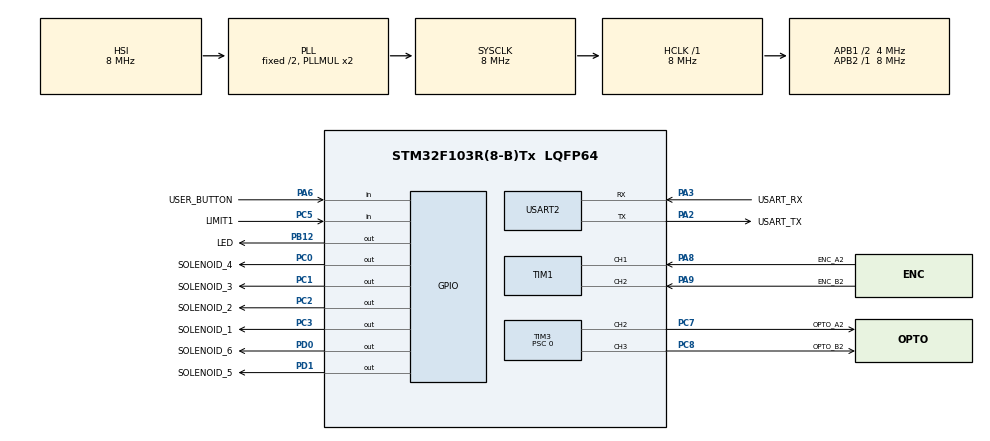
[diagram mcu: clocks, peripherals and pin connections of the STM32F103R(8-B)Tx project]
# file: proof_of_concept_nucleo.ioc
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Mcu.Family=STM32F1
Mcu.Name=STM32F103R(8-B)Tx
Mcu.Package=LQFP64
NVIC.PriorityGroup=NVIC_PRIORITYGROUP_4
NVIC.TIM4_IRQn=true\:0\:0\:false\:false\:true\:true\:true\:true
PA13.Mode=Serial_Wire
PA13.Signal=SYS_JTMS-SWDIO
PA14.Mode=Serial_Wire
PA14.Signal=SYS_JTCK-SWCLK
PA2.GPIO_Label=USART_TX
PA2.GPIO_Mode=GPIO_MODE_AF_PP
PA2.GPIO_PuPd=GPIO_NOPULL
PA2.GPIO_Speed=GPIO_SPEED_FREQ_LOW
PA2.Mode=Asynchronous
PA2.Signal=USART2_TX
PA3.GPIO_Label=USART_RX
PA3.GPIO_Mode=GPIO_MODE_AF_PP
PA3.GPIO_PuPd=GPIO_NOPULL
PA3.GPIO_Speed=GPIO_SPEED_FREQ_LOW
PA3.Mode=Asynchronous
PA3.Signal=USART2_RX
PA6.GPIO_Label=USER_BUTTON
PA6.Signal=GPIO_Input
PA8.GPIO_Label=ENC_A2
PA8.Signal=S_TIM1_CH1
PA9.GPIO_Label=ENC_B2
PA9.Signal=S_TIM1_CH2
PB12.GPIO_Label=LED
PB12.Signal=GPIO_Output
PC0.GPIO_Label=SOLENOID_4
PC0.Signal=GPIO_Output
PC1.GPIO_Label=SOLENOID_3
PC1.Signal=GPIO_Output
PC2.GPIO_Label=SOLENOID_2
PC2.Signal=GPIO_Output
PC3.GPIO_Label=SOLENOID_1
PC3.Signal=GPIO_Output
PC5.GPIO_Label=LIMIT1
PC5.Signal=GPIO_Input
PC7.GPIO_Label=OPTO_A2
PC7.Signal=S_TIM3_CH2
PC8.GPIO_Label=OPTO_B2
PC8.Signal=S_TIM3_CH3
PD0-OSC_IN.GPIO_Label=SOLENOID_6
PD0-OSC_IN.Signal=GPIO_Output
PD1-OSC_OUT.GPIO_Label=SOLENOID_5
PD1-OSC_OUT.Signal=GPIO_Output
ProjectManager.HeapSize=0x200
ProjectManager.StackSize=0x400
ProjectManager.TargetToolchain=STM32CubeIDE
RCC.AHBFreq_Value=8000000
RCC.APB1CLKDivider=RCC_HCLK_DIV2
RCC.APB1Freq_Value=4000000
RCC.APB1TimFreq_Value=8000000
RCC.APB2Freq_Value=8000000
RCC.APB2TimFreq_Value=8000000
RCC.HCLKFreq_Value=8000000
RCC.RTCClockSelection=RCC_RTCCLKSOURCE_LSE
RCC.SYSCLKFreq_VALUE=8000000
RCC.SYSCLKSource=RCC_SYSCLKSOURCE_PLLCLK
RCC.USBFreq_Value=8000000
SH.S_TIM1_CH1.0=TIM1_CH1,Encoder_Interface
SH.S_TIM1_CH2.0=TIM1_CH2,Encoder_Interface
SH.S_TIM3_CH2.0=TIM3_CH2,PWM Generation2 CH2
SH.S_TIM3_CH3.0=TIM3_CH3,PWM Generation3 CH3
TIM1.IC1Filter=8
TIM1.IC2Filter=4
TIM2.AutoReloadPreload=TIM_AUTORELOAD_PRELOAD_ENABLE
TIM2.Prescaler=0
TIM3.AutoReloadPreload=TIM_AUTORELOAD_PRELOAD_ENABLE
TIM3.Channel-PWM\ Generation2\ CH2=TIM_CHANNEL_2
TIM3.Channel-PWM\ Generation3\ CH3=TIM_CHANNEL_3
TIM3.Prescaler=0
TIM4.AutoReloadPreload=TIM_AUTORELOAD_PRELOAD_ENABLE
TIM4.Period=999
TIM4.Prescaler=7
USART2.VirtualMode=VM_ASYNC
VP_TIM2_VS_ClockSourceINT.Mode=Internal
VP_TIM3_VS_ClockSourceINT.Mode=Internal
VP_TIM4_VS_ClockSourceINT.Mode=Internal
board=NUCLEO-F103RB

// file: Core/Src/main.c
/* USER CODE BEGIN Header */
/**
  ******************************************************************************
  * @file           : main.c
  * @brief          : Main program body
  ******************************************************************************
  * @attention
  *
  * Copyright (c) 2026 STMicroelectronics.
  * All rights reserved.
  *
  * This software is licensed under terms that can be found in the LICENSE file
  * in the root directory of this software component.
  * If no LICENSE file comes with this software, it is provided AS-IS.
  *
  ******************************************************************************
  */
/* USER CODE END Header */
#include "main.h"
#include "tim.h"
#include "usart.h"
#include "gpio.h"
#include "song_player.h"
/* USER CODE BEGIN Includes */

#include "motor_control.h"
#include "pid.h"

/* USER CODE END Includes */

/* USER CODE BEGIN PV */
int32_t pos_counts;
/* USER CODE END PV */

void SystemClock_Config(void);

int main(void)
{

  /* MCU Configuration--------------------------------------------------------*/

  /* Reset of all peripherals, Initializes the Flash interface and the Systick. */
  HAL_Init();

  /* Configure the system clock */
  SystemClock_Config();

  /* Initialize all configured peripherals */
  MX_GPIO_Init();
  MX_USART2_UART_Init();
  MX_TIM2_Init();
  MX_TIM3_Init();
  MX_TIM1_Init();
  MX_TIM4_Init();
  /* USER CODE BEGIN 2 */

  motor_control_init();
  HAL_TIM_Base_Start_IT(&htim4);

  test_printKeyMap();   // prints key map over UART — confirms comms working
  test_playScale();     // moves motor through C major scale

  /* USER CODE END 2 */

  /* Infinite loop */
  /* USER CODE BEGIN WHILE */
//  float motor_speed = 0.5;
  while (1)
  {
    HAL_GPIO_TogglePin(GPIOC, GPIO_PIN_0);
    HAL_Delay(1000);
    /* USER CODE END WHILE */

  }
}

void SystemClock_Config(void)
{
  RCC_OscInitTypeDef RCC_OscInitStruct = {0};
  RCC_ClkInitTypeDef RCC_ClkInitStruct = {0};

  /** Initializes the RCC Oscillators according to the specified parameters
  * in the RCC_OscInitTypeDef structure.
  */
  RCC_OscInitStruct.OscillatorType = RCC_OSCILLATORTYPE_HSI;
  RCC_OscInitStruct.HSIState = RCC_HSI_ON;
  RCC_OscInitStruct.HSICalibrationValue = RCC_HSICALIBRATION_DEFAULT;
  RCC_OscInitStruct.PLL.PLLState = RCC_PLL_ON;
  RCC_OscInitStruct.PLL.PLLSource = RCC_PLLSOURCE_HSI_DIV2;
  RCC_OscInitStruct.PLL.PLLMUL = RCC_PLL_MUL2;
  if (HAL_RCC_OscConfig(&RCC_OscInitStruct) != HAL_OK)
  {
    Error_Handler();
  }

  /** Initializes the CPU, AHB and APB buses clocks
  */
  RCC_ClkInitStruct.ClockType = RCC_CLOCKTYPE_HCLK|RCC_CLOCKTYPE_SYSCLK
                              |RCC_CLOCKTYPE_PCLK1|RCC_CLOCKTYPE_PCLK2;
  RCC_ClkInitStruct.SYSCLKSource = RCC_SYSCLKSOURCE_PLLCLK;
  RCC_ClkInitStruct.AHBCLKDivider = RCC_SYSCLK_DIV1;
  RCC_ClkInitStruct.APB1CLKDivider = RCC_HCLK_DIV2;
  RCC_ClkInitStruct.APB2CLKDivider = RCC_HCLK_DIV1;

  if (HAL_RCC_ClockConfig(&RCC_ClkInitStruct, FLASH_LATENCY_0) != HAL_OK)
  {
    Error_Handler();
  }
}

void Error_Handler(void)
{
  __disable_irq();
  while (1)
  {
  }
}
